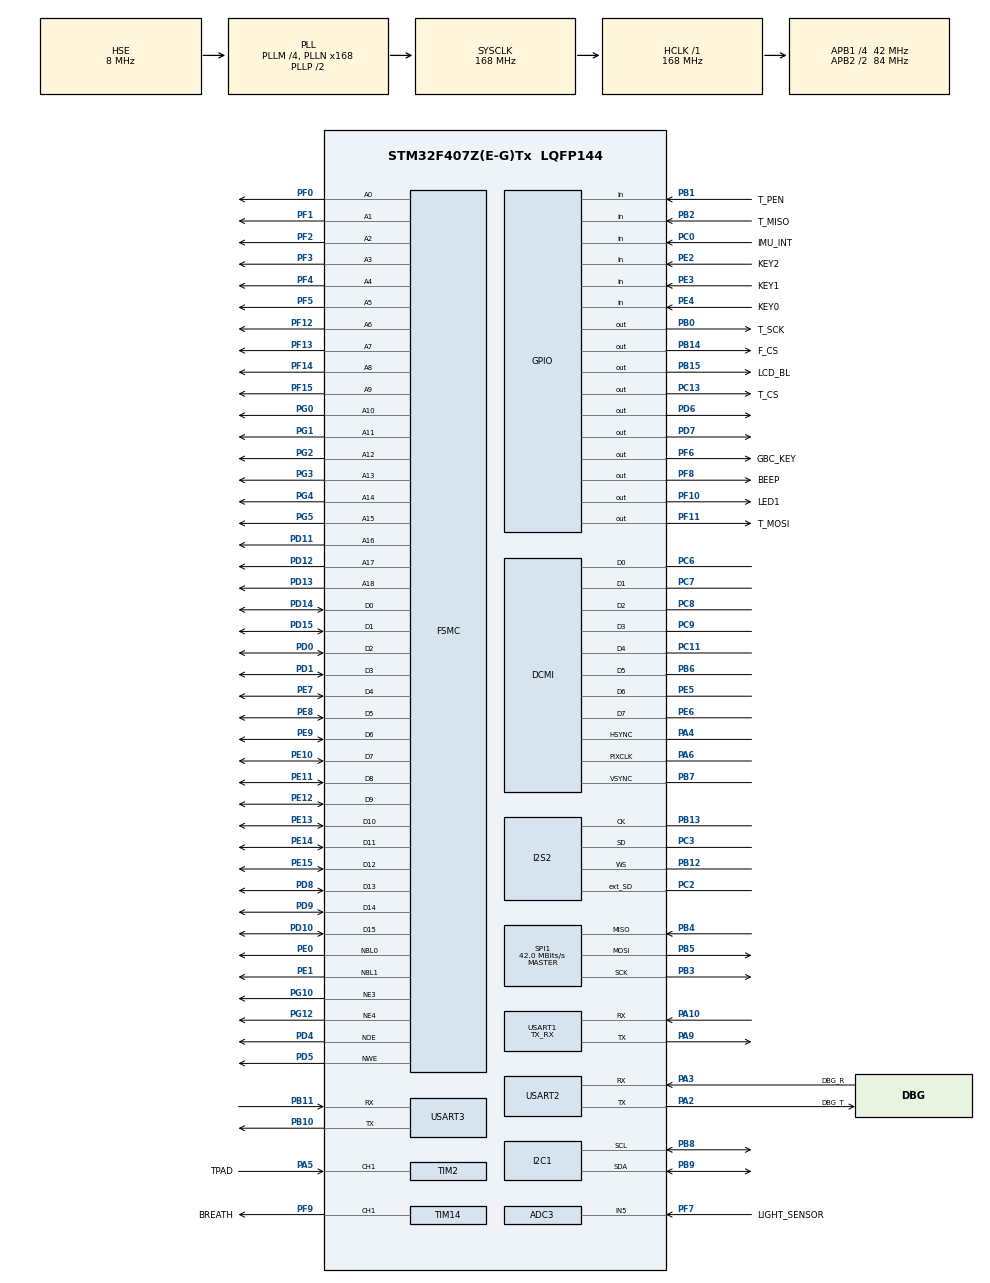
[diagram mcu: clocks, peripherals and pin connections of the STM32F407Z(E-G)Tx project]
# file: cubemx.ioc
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ADC3.Channel-0\#ChannelRegularConversion=ADC_CHANNEL_5
ADC3.NbrOfConversionFlag=1
ADC3.Rank-0\#ChannelRegularConversion=1
ADC3.SamplingTime-0\#ChannelRegularConversion=ADC_SAMPLETIME_3CYCLES
DCMI.JPEGMode=DCMI_JPEG_DISABLE
DCMI.PCKPolarity=DCMI_PCKPOLARITY_RISING
Dma.DCMI.0.Direction=DMA_PERIPH_TO_MEMORY
Dma.DCMI.0.FIFOMode=DMA_FIFOMODE_ENABLE
Dma.DCMI.0.FIFOThreshold=DMA_FIFO_THRESHOLD_HALFFULL
Dma.DCMI.0.Instance=DMA2_Stream1
Dma.DCMI.0.MemBurst=DMA_MBURST_SINGLE
Dma.DCMI.0.MemDataAlignment=DMA_MDATAALIGN_WORD
Dma.DCMI.0.MemInc=DMA_MINC_ENABLE
Dma.DCMI.0.Mode=DMA_NORMAL
Dma.DCMI.0.PeriphBurst=DMA_PBURST_SINGLE
Dma.DCMI.0.PeriphDataAlignment=DMA_PDATAALIGN_WORD
Dma.DCMI.0.PeriphInc=DMA_PINC_DISABLE
Dma.DCMI.0.Priority=DMA_PRIORITY_LOW
Dma.Request0=DCMI
FREERTOS.Tasks01=defaultTask,24,128,StartDefaultTask,Default,NULL,Dynamic,NULL,NULL
FSMC.AddressSetupTime1=1
FSMC.AddressSetupTime3=0
FSMC.BusTurnAroundDuration1=0
FSMC.BusTurnAroundDuration3=0
FSMC.DataSetupTime1=7
FSMC.DataSetupTime3=7
FSMC.ExtendedMode1=FSMC_EXTENDED_MODE_DISABLE
FSMC.WriteOperation3=FSMC_WRITE_OPERATION_ENABLE
I2S2.AudioFreq=I2S_AUDIOFREQ_96K
I2S2.ErrorAudioFreq=-0.79 %
I2S2.FullDuplexMode=I2S_FULLDUPLEXMODE_ENABLE
I2S2.Instance=SPI$Index
I2S2.RealAudioFreq=95.238 KHz
I2S2.VirtualMode=I2S_MODE_MASTER
Mcu.Family=STM32F4
Mcu.Name=STM32F407Z(E-G)Tx
Mcu.Package=LQFP144
NVIC.DMA2_Stream1_IRQn=true\:5\:0\:false\:false\:true\:true\:false\:true
NVIC.PriorityGroup=NVIC_PRIORITYGROUP_4
NVIC.TIM8_UP_TIM13_IRQn=true\:5\:0\:false\:false\:true\:true\:true\:true
PA0-WKUP.GPIO_Label=WKUP
PA0-WKUP.Mode=SYS_WakeUp0
PA0-WKUP.Signal=SYS_WKUP
PA10.GPIO_PuPd=GPIO_PULLUP
PA10.Mode=Asynchronous
PA10.Signal=USART1_RX
PA13.Mode=Serial_Wire
PA13.Signal=SYS_JTMS-SWDIO
PA14.Mode=Serial_Wire
PA14.Signal=SYS_JTCK-SWCLK
PA2.GPIO_Label=DBG_T
PA2.Mode=Asynchronous
PA2.Signal=USART2_TX
PA3.GPIO_Label=DBG_R
PA3.Mode=Asynchronous
PA3.Signal=USART2_RX
PA4.Mode=Slave_8_bits_External_Synchro
PA4.Signal=DCMI_HSYNC
PA5.GPIO_Label=TPAD
PA5.Signal=S_TIM2_CH1_ETR
PA6.Mode=Slave_8_bits_External_Synchro
PA6.Signal=DCMI_PIXCLK
PA7.Signal=ETH_CRS_DV
PA9.GPIO_PuPd=GPIO_PULLUP
PA9.Mode=Asynchronous
PA9.Signal=USART1_TX
PB0.GPIO_Label=T_SCK
PB0.Signal=GPIO_Output
PB1.GPIO_Label=T_PEN
PB1.GPIO_PuPd=GPIO_PULLUP
PB1.Signal=GPIO_Input
PB10.Mode=Asynchronous
PB10.Signal=USART3_TX
PB11.Mode=Asynchronous
PB11.Signal=USART3_RX
PB12.Mode=Full_Duplex_Master
PB12.Signal=I2S2_WS
PB13.Mode=Full_Duplex_Master
PB13.Signal=I2S2_CK
PB14.GPIO_Label=F_CS
PB14.Signal=GPIO_Output
PB15.GPIO_Label=LCD_BL
PB15.GPIO_PuPd=GPIO_PULLUP
PB15.GPIO_Speed=GPIO_SPEED_FREQ_LOW
PB15.PinState=GPIO_PIN_SET
PB15.Signal=GPIO_Output
PB2.GPIO_Label=T_MISO
PB2.Signal=GPIO_Input
PB3.Mode=Full_Duplex_Master
PB3.Signal=SPI1_SCK
PB4.Mode=Full_Duplex_Master
PB4.Signal=SPI1_MISO
PB5.Mode=Full_Duplex_Master
PB5.Signal=SPI1_MOSI
PB6.Mode=Slave_8_bits_External_Synchro
PB6.Signal=DCMI_D5
PB7.Mode=Slave_8_bits_External_Synchro
PB7.Signal=DCMI_VSYNC
PB8.Mode=I2C
PB8.Signal=I2C1_SCL
PB9.Mode=I2C
PB9.Signal=I2C1_SDA
PC0.GPIO_Label=IMU_INT
PC0.Signal=GPIO_Input
PC11.Mode=Slave_8_bits_External_Synchro
PC11.Signal=DCMI_D4
PC13-ANTI_TAMP.GPIO_Label=T_CS
PC13-ANTI_TAMP.GPIO_PuPd=GPIO_NOPULL
PC13-ANTI_TAMP.Signal=GPIO_Output
PC14-OSC32_IN.Mode=LSE-External-Oscillator
PC14-OSC32_IN.Signal=RCC_OSC32_IN
PC15-OSC32_OUT.Mode=LSE-External-Oscillator
PC15-OSC32_OUT.Signal=RCC_OSC32_OUT
PC2.Mode=Full_Duplex_Master
PC2.Signal=I2S2_ext_SD
PC3.Mode=Full_Duplex_Master
PC3.Signal=I2S2_SD
PC4.Signal=ETH_RXD0
PC5.Signal=ETH_RXD1
PC6.Mode=Slave_8_bits_External_Synchro
PC6.Signal=DCMI_D0
PC7.Mode=Slave_8_bits_External_Synchro
PC7.Signal=DCMI_D1
PC8.Mode=Slave_8_bits_External_Synchro
PC8.Signal=DCMI_D2
PC9.Mode=Slave_8_bits_External_Synchro
PC9.Signal=DCMI_D3
PD0.Signal=FSMC_D2_DA2
PD1.Signal=FSMC_D3_DA3
PD10.Signal=FSMC_D15_DA15
PD11.Signal=FSMC_A16_CLE
PD12.Signal=FSMC_A17_ALE
PD13.Signal=FSMC_A18
PD14.Signal=FSMC_D0_DA0
PD15.Signal=FSMC_D1_DA1
PD4.Signal=FSMC_NOE
PD5.Signal=FSMC_NWE
PD6.Signal=GPIO_Output
PD7.Signal=GPIO_Output
PD8.Signal=FSMC_D13_DA13
PD9.Signal=FSMC_D14_DA14
PE0.Signal=FSMC_NBL0
PE1.Signal=FSMC_NBL1
PE10.Signal=FSMC_D7_DA7
PE11.Signal=FSMC_D8_DA8
PE12.Signal=FSMC_D9_DA9
PE13.Signal=FSMC_D10_DA10
PE14.Signal=FSMC_D11_DA11
PE15.Signal=FSMC_D12_DA12
PE2.GPIO_Label=KEY2
PE2.GPIO_PuPd=GPIO_PULLUP
PE2.Signal=GPIO_Input
PE3.GPIO_Label=KEY1
PE3.GPIO_PuPd=GPIO_PULLUP
PE3.Signal=GPIO_Input
PE4.GPIO_Label=KEY0
PE4.GPIO_PuPd=GPIO_PULLUP
PE4.Signal=GPIO_Input
PE5.Mode=Slave_8_bits_External_Synchro
PE5.Signal=DCMI_D6
PE6.Mode=Slave_8_bits_External_Synchro
PE6.Signal=DCMI_D7
PE7.Signal=FSMC_D4_DA4
PE8.Signal=FSMC_D5_DA5
PE9.Signal=FSMC_D6_DA6
PF0.Signal=FSMC_A0
PF1.Signal=FSMC_A1
PF10.GPIO_Label=LED1
PF10.Signal=GPIO_Output
PF11.GPIO_Label=T_MOSI
PF11.Signal=GPIO_Output
PF12.Signal=FSMC_A6
PF13.Signal=FSMC_A7
PF14.Signal=FSMC_A8
PF15.Signal=FSMC_A9
PF2.Signal=FSMC_A2
PF3.Signal=FSMC_A3
PF4.Signal=FSMC_A4
PF5.Signal=FSMC_A5
PF6.GPIO_Label=GBC_KEY
PF6.Signal=GPIO_Output
PF7.GPIO_Label=LIGHT_SENSOR
PF7.Mode=IN5
PF7.Signal=ADC3_IN5
PF8.GPIO_Label=BEEP
PF8.Signal=GPIO_Output
PF9.GPIO_Label=BREATH
PF9.Signal=S_TIM14_CH1
PG0.Signal=FSMC_A10
PG1.Signal=FSMC_A11
PG10.Mode=NorPsramChipSelect3_3
PG10.Signal=FSMC_NE3
PG12.Mode=NorPsramChipSelect4_1
PG12.Signal=FSMC_NE4
PG2.Signal=FSMC_A12
PG3.Signal=FSMC_A13
PG4.Signal=FSMC_A14
PG5.Signal=FSMC_A15
PH0-OSC_IN.Mode=HSE-External-Oscillator
PH0-OSC_IN.Signal=RCC_OSC_IN
PH1-OSC_OUT.Mode=HSE-External-Oscillator
PH1-OSC_OUT.Signal=RCC_OSC_OUT
ProjectManager.HeapSize=0x200
ProjectManager.StackSize=0x400
ProjectManager.TargetToolchain=Makefile
RCC.48MHZClocksFreq_Value=48000000
RCC.AHBFreq_Value=168000000
RCC.APB1CLKDivider=RCC_HCLK_DIV4
RCC.APB1Freq_Value=42000000
RCC.APB1TimFreq_Value=84000000
RCC.APB2CLKDivider=RCC_HCLK_DIV2
RCC.APB2Freq_Value=84000000
RCC.APB2TimFreq_Value=168000000
RCC.CortexFreq_Value=168000000
RCC.HCLKFreq_Value=168000000
RCC.HSE_VALUE=8000000
RCC.HSI_VALUE=16000000
RCC.PLLM=4
RCC.PLLN=168
RCC.PLLQ=7
RCC.PLLSourceVirtual=RCC_PLLSOURCE_HSE
RCC.RCC_RTC_Clock_Source=RCC_RTCCLKSOURCE_LSE
RCC.RCC_RTC_Clock_SourceVirtual=RCC_RTCCLKSOURCE_LSE
RCC.SYSCLKFreq_VALUE=168000000
RCC.SYSCLKSource=RCC_SYSCLKSOURCE_PLLCLK
RCC.VCOOutputFreq_Value=336000000
RTC.Format=RTC_FORMAT_BIN
SH.FSMC_A0.0=FSMC_A0,19b-a3
SH.FSMC_A1.0=FSMC_A1,19b-a3
SH.FSMC_A10.0=FSMC_A10,19b-a3
SH.FSMC_A11.0=FSMC_A11,19b-a3
SH.FSMC_A12.0=FSMC_A12,19b-a3
SH.FSMC_A13.0=FSMC_A13,19b-a3
SH.FSMC_A14.0=FSMC_A14,19b-a3
SH.FSMC_A15.0=FSMC_A15,19b-a3
SH.FSMC_A16_CLE.0=FSMC_A16,19b-a3
SH.FSMC_A17_ALE.0=FSMC_A17,19b-a3
SH.FSMC_A18.0=FSMC_A18,19b-a3
SH.FSMC_A2.0=FSMC_A2,19b-a3
SH.FSMC_A3.0=FSMC_A3,19b-a3
SH.FSMC_A4.0=FSMC_A4,19b-a3
SH.FSMC_A5.0=FSMC_A5,19b-a3
SH.FSMC_A6.0=FSMC_A6,A6_1
SH.FSMC_A6.1=FSMC_A6,19b-a3
SH.FSMC_A7.0=FSMC_A7,19b-a3
SH.FSMC_A8.0=FSMC_A8,19b-a3
SH.FSMC_A9.0=FSMC_A9,19b-a3
SH.FSMC_D0_DA0.0=FSMC_D0,16b-d1
SH.FSMC_D0_DA0.1=FSMC_D0,16b-d3
SH.FSMC_D10_DA10.0=FSMC_D10,16b-d1
SH.FSMC_D10_DA10.1=FSMC_D10,16b-d3
SH.FSMC_D11_DA11.0=FSMC_D11,16b-d1
SH.FSMC_D11_DA11.1=FSMC_D11,16b-d3
SH.FSMC_D12_DA12.0=FSMC_D12,16b-d1
SH.FSMC_D12_DA12.1=FSMC_D12,16b-d3
SH.FSMC_D13_DA13.0=FSMC_D13,16b-d1
SH.FSMC_D13_DA13.1=FSMC_D13,16b-d3
SH.FSMC_D14_DA14.0=FSMC_D14,16b-d1
SH.FSMC_D14_DA14.1=FSMC_D14,16b-d3
SH.FSMC_D15_DA15.0=FSMC_D15,16b-d1
SH.FSMC_D15_DA15.1=FSMC_D15,16b-d3
SH.FSMC_D1_DA1.0=FSMC_D1,16b-d1
SH.FSMC_D1_DA1.1=FSMC_D1,16b-d3
SH.FSMC_D2_DA2.0=FSMC_D2,16b-d1
SH.FSMC_D2_DA2.1=FSMC_D2,16b-d3
SH.FSMC_D3_DA3.0=FSMC_D3,16b-d1
SH.FSMC_D3_DA3.1=FSMC_D3,16b-d3
SH.FSMC_D4_DA4.0=FSMC_D4,16b-d1
SH.FSMC_D4_DA4.1=FSMC_D4,16b-d3
SH.FSMC_D5_DA5.0=FSMC_D5,16b-d1
SH.FSMC_D5_DA5.1=FSMC_D5,16b-d3
SH.FSMC_D6_DA6.0=FSMC_D6,16b-d1
SH.FSMC_D6_DA6.1=FSMC_D6,16b-d3
SH.FSMC_D7_DA7.0=FSMC_D7,16b-d1
SH.FSMC_D7_DA7.1=FSMC_D7,16b-d3
SH.FSMC_D8_DA8.0=FSMC_D8,16b-d1
SH.FSMC_D8_DA8.1=FSMC_D8,16b-d3
SH.FSMC_D9_DA9.0=FSMC_D9,16b-d1
SH.FSMC_D9_DA9.1=FSMC_D9,16b-d3
SH.FSMC_NBL0.0=FSMC_NBL0,2ByteEnable3
SH.FSMC_NBL1.0=FSMC_NBL1,2ByteEnable3
SH.FSMC_NOE.0=FSMC_NOE,Lcd1
SH.FSMC_NOE.1=FSMC_NOE,Sram3
SH.FSMC_NWE.0=FSMC_NWE,Lcd1
SH.FSMC_NWE.1=FSMC_NWE,Sram3
SH.S_TIM14_CH1.0=TIM14_CH1,PWM Generation1 CH1
SH.S_TIM2_CH1_ETR.0=TIM2_CH1,Input_Capture1_from_TI1
SPI1.CalculateBaudRate=42.0 MBits/s
SPI1.Direction=SPI_DIRECTION_2LINES
SPI1.Mode=SPI_MODE_MASTER
SPI1.VirtualType=VM_MASTER
TIM13.AutoReloadPreload=TIM_AUTORELOAD_PRELOAD_ENABLE
TIM13.Period=10000
TIM13.Prescaler=84-1
TIM14.AutoReloadPreload=TIM_AUTORELOAD_PRELOAD_ENABLE
TIM14.Channel=TIM_CHANNEL_1
TIM14.Prescaler=9999
TIM14.Pulse=0
TIM2.AutoReloadPreload=TIM_AUTORELOAD_PRELOAD_ENABLE
TIM2.Channel-Input_Capture1_from_TI1=TIM_CHANNEL_1
TIM2.Period=0xffffffff
TIM2.Prescaler=7
TIM2.TIM_MasterOutputTrigger=TIM_TRGO_RESET
USART1.Mode=MODE_TX_RX
USART1.VirtualMode=VM_ASYNC
USART2.VirtualMode=VM_ASYNC
USART3.VirtualMode=VM_ASYNC
VP_FREERTOS_VS_CMSIS_V2.Mode=CMSIS_V2
VP_RNG_VS_RNG.Mode=RNG_Activate
VP_RTC_VS_RTC_Activate.Mode=RTC_Enabled
VP_RTC_VS_RTC_Calendar.Mode=RTC_Calendar
VP_TIM10_VS_ClockSourceINT.Mode=Enable_Timer
VP_TIM11_VS_ClockSourceINT.Mode=Enable_Timer
VP_TIM13_VS_ClockSourceINT.Mode=Enable_Timer
VP_TIM14_VS_ClockSourceINT.Mode=Enable_Timer
VP_TIM6_VS_ClockSourceINT.Mode=Enable_Timer
VP_TIM7_VS_ClockSourceINT.Mode=Enable_Timer
board=custom

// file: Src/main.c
/* USER CODE BEGIN Header */
/**
 ******************************************************************************
 * @file           : main.c
 * @brief          : Main program body
 ******************************************************************************
 * @attention
 *
 * <h2><center>&copy; Copyright (c) 2022 STMicroelectronics.
 * All rights reserved.</center></h2>
 *
 * This software component is licensed by ST under BSD 3-Clause license,
 * the "License"; You may not use this file except in compliance with the
 * License. You may obtain a copy of the License at:
 *                        opensource.org/licenses/BSD-3-Clause
 *
 ******************************************************************************
 */
/* USER CODE END Header */
#include "main.h"
#include "cmsis_os.h"
#include "adc.h"
#include "dcmi.h"
#include "dma.h"
#include "i2c.h"
#include "i2s.h"
#include "rng.h"
#include "rtc.h"
#include "spi.h"
#include "tim.h"
#include "usart.h"
#include "gpio.h"
#include "fsmc.h"

/* USER CODE BEGIN Includes */
#include "app_main.h"
/* USER CODE END Includes */

void SystemClock_Config(void);
void MX_FREERTOS_Init(void);

int main(void)
{

  /* MCU Configuration--------------------------------------------------------*/

  /* Reset of all peripherals, Initializes the Flash interface and the Systick. */
  HAL_Init();

  /* Configure the system clock */
  SystemClock_Config();

  /* Initialize all configured peripherals */
  MX_GPIO_Init();
  MX_DMA_Init();
  MX_USART1_UART_Init();
  MX_FSMC_Init();
  MX_TIM14_Init();
  MX_TIM2_Init();
  MX_RTC_Init();
  MX_USART2_UART_Init();
  MX_DCMI_Init();
  MX_ADC3_Init();
  MX_I2C1_Init();
  MX_I2S2_Init();
  MX_SPI1_Init();
  MX_TIM6_Init();
  MX_TIM7_Init();
  MX_TIM10_Init();
  MX_TIM11_Init();
  MX_TIM13_Init();
  MX_USART3_UART_Init();
  MX_RNG_Init();

  /* Init scheduler */
  osKernelInitialize();  /* Call init function for freertos objects (in freertos.c) */
  MX_FREERTOS_Init();
  /* Start scheduler */
  osKernelStart();

  /* We should never get here as control is now taken by the scheduler */
  /* Infinite loop */
        while (1) {

        }
}

void SystemClock_Config(void)
{
  RCC_OscInitTypeDef RCC_OscInitStruct = {0};
  RCC_ClkInitTypeDef RCC_ClkInitStruct = {0};
  RCC_PeriphCLKInitTypeDef PeriphClkInitStruct = {0};

  /** Configure the main internal regulator output voltage
  */
  __HAL_RCC_PWR_CLK_ENABLE();
  __HAL_PWR_VOLTAGESCALING_CONFIG(PWR_REGULATOR_VOLTAGE_SCALE1);
  /** Initializes the RCC Oscillators according to the specified parameters
  * in the RCC_OscInitTypeDef structure.
  */
  RCC_OscInitStruct.OscillatorType = RCC_OSCILLATORTYPE_HSE|RCC_OSCILLATORTYPE_LSE;
  RCC_OscInitStruct.HSEState = RCC_HSE_ON;
  RCC_OscInitStruct.LSEState = RCC_LSE_ON;
  RCC_OscInitStruct.PLL.PLLState = RCC_PLL_ON;
  RCC_OscInitStruct.PLL.PLLSource = RCC_PLLSOURCE_HSE;
  RCC_OscInitStruct.PLL.PLLM = 4;
  RCC_OscInitStruct.PLL.PLLN = 168;
  RCC_OscInitStruct.PLL.PLLP = RCC_PLLP_DIV2;
  RCC_OscInitStruct.PLL.PLLQ = 7;
  if (HAL_RCC_OscConfig(&RCC_OscInitStruct) != HAL_OK)
  {
    Error_Handler();
  }
  /** Initializes the CPU, AHB and APB buses clocks
  */
  RCC_ClkInitStruct.ClockType = RCC_CLOCKTYPE_HCLK|RCC_CLOCKTYPE_SYSCLK
                              |RCC_CLOCKTYPE_PCLK1|RCC_CLOCKTYPE_PCLK2;
  RCC_ClkInitStruct.SYSCLKSource = RCC_SYSCLKSOURCE_PLLCLK;
  RCC_ClkInitStruct.AHBCLKDivider = RCC_SYSCLK_DIV1;
  RCC_ClkInitStruct.APB1CLKDivider = RCC_HCLK_DIV4;
  RCC_ClkInitStruct.APB2CLKDivider = RCC_HCLK_DIV2;

  if (HAL_RCC_ClockConfig(&RCC_ClkInitStruct, FLASH_LATENCY_5) != HAL_OK)
  {
    Error_Handler();
  }
  PeriphClkInitStruct.PeriphClockSelection = RCC_PERIPHCLK_I2S|RCC_PERIPHCLK_RTC;
  PeriphClkInitStruct.PLLI2S.PLLI2SN = 192;
  PeriphClkInitStruct.PLLI2S.PLLI2SR = 2;
  PeriphClkInitStruct.RTCClockSelection = RCC_RTCCLKSOURCE_LSE;
  if (HAL_RCCEx_PeriphCLKConfig(&PeriphClkInitStruct) != HAL_OK)
  {
    Error_Handler();
  }
}

void Error_Handler(void)
{
  /* USER CODE BEGIN Error_Handler_Debug */
    /* User can add his own implementation to report the HAL error return state
     */
    __disable_irq();
        while (1) {}
  /* USER CODE END Error_Handler_Debug */
}

#ifdef  USE_FULL_ASSERT
/**
  * @brief  Reports the name of the source file and the source line number
  *         where the assert_param error has occurred.
  * @param  file: pointer to the source file name
  * @param  line: assert_param error line source number
  * @retval None
  */
void assert_failed(uint8_t *file, uint32_t line)
{
  /* USER CODE BEGIN 6 */
    /* User can add his own implementation to report the file name and line
       number, ex: printf("Wrong parameters value: file %s on line %d\r\n",
       file, line) */
  /* USER CODE END 6 */
}
#endif /* USE_FULL_ASSERT */

/************************ (C) COPYRIGHT STMicroelectronics *****END OF FILE****/

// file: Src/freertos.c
/* USER CODE BEGIN Header */
/**
 ******************************************************************************
 * File Name          : freertos.c
 * Description        : Code for freertos applications
 ******************************************************************************
 * @attention
 *
 * <h2><center>&copy; Copyright (c) 2022 STMicroelectronics.
 * All rights reserved.</center></h2>
 *
 * This software component is licensed by ST under Ultimate Liberty license
 * SLA0044, the "License"; You may not use this file except in compliance with
 * the License. You may obtain a copy of the License at:
 *                             www.st.com/SLA0044
 *
 ******************************************************************************
 */
/* USER CODE END Header */

#include "FreeRTOS.h"
#include "task.h"
#include "main.h"
#include "cmsis_os.h"

/* Definitions for defaultTask */
osThreadId_t defaultTaskHandle;
const osThreadAttr_t defaultTask_attributes = {
  .name = "defaultTask",
  .stack_size = 128 * 4,
  .priority = (osPriority_t) osPriorityNormal,
};

void StartDefaultTask(void *argument);

void MX_FREERTOS_Init(void); /* (MISRA C 2004 rule 8.1) */

void MX_FREERTOS_Init(void) {

  /* Create the thread(s) */
  /* creation of defaultTask */
  defaultTaskHandle = osThreadNew(StartDefaultTask, NULL, &defaultTask_attributes);

}

void StartDefaultTask(void *argument)
{
  /* USER CODE BEGIN StartDefaultTask */
        /* Infinite loop */
        for (;;) {
            extern int app_main(void);
            app_main();
            osDelay(1);
        }
  /* USER CODE END StartDefaultTask */
}

/************************ (C) COPYRIGHT STMicroelectronics *****END OF FILE****/
